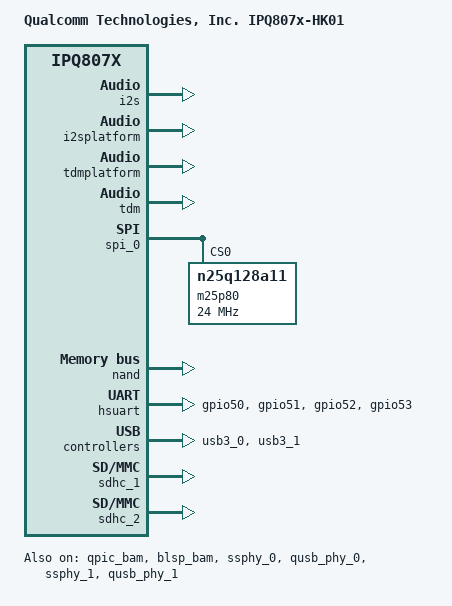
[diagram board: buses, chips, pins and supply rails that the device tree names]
/dts-v1/;
/*
 * Copyright (c) 2016, The Linux Foundation. All rights reserved.
 *
 * Permission to use, copy, modify, and/or distribute this software for any
 * purpose with or without fee is hereby granted, provided that the above
 * copyright notice and this permission notice appear in all copies.
 *
 * THE SOFTWARE IS PROVIDED "AS IS" AND THE AUTHOR DISCLAIMS ALL WARRANTIES
 * WITH REGARD TO THIS SOFTWARE INCLUDING ALL IMPLIED WARRANTIES OF
 * MERCHANTABILITY AND FITNESS. IN NO EVENT SHALL THE AUTHOR BE LIABLE FOR
 * ANY SPECIAL, DIRECT, INDIRECT, OR CONSEQUENTIAL DAMAGES OR ANY DAMAGES
 * WHATSOEVER RESULTING FROM LOSS OF USE, DATA OR PROFITS, WHETHER IN AN
 * ACTION OF CONTRACT, NEGLIGENCE OR OTHER TORTIOUS ACTION, ARISING OUT OF
 * OR IN CONNECTION WITH THE USE OR PERFORMANCE OF THIS SOFTWARE.
 */
#include "qcom-ipq807x-soc.dtsi"

/ {
	#address-cells = <0x2>;
	#size-cells = <0x2>;
	model = "Qualcomm Technologies, Inc. IPQ807x-HK01";
	compatible = "qcom,ipq807x-hk01", "qcom,ipq807x";
	qcom,msm-id = <0x125 0x0>;
	interrupt-parent = <&intc>;
	qcom,board-id = <0x10 0x0>;

	aliases {
		sdhc1 = &sdhc_1; /* SDC1 eMMC slot */
		sdhc2 = &sdhc_2; /* SDC2 SD slot */
	};

	cpus {
		#address-cells = <0x1>;
		#size-cells = <0x0>;

		cpu-map {

			cluster0 {

				core0 {
					cpu = <&CPU0>;
				};

				core1 {
					cpu = <&CPU1>;
				};

				core2 {
					cpu = <&CPU2>;
				};

				core3 {
					cpu = <&CPU3>;
				};
			};

		};

		CPU0: cpu@0 {
			device_type = "cpu";
			compatible = "arm,cortex-a53";
			reg = <0x0>;
			enable-method = "qcom,arm-cortex-acc";
			qcom,acc = <&acc0>;
			next-level-cache = <&L2_0>;

			L2_0: l2-cache {
				compatible = "arm,arch-cache";
				cache-level = <0x2>;
			};
		};

		CPU1: cpu@1 {
			device_type = "cpu";
			compatible = "arm,cortex-a53";
			enable-method = "qcom,arm-cortex-acc";
			reg = <0x1>;
			qcom,acc = <&acc1>;
			next-level-cache = <&L2_0>;
		};

		CPU2: cpu@2 {
			device_type = "cpu";
			compatible = "arm,cortex-a53";
			enable-method = "qcom,arm-cortex-acc";
			reg = <0x2>;
			qcom,acc = <&acc2>;
			next-level-cache = <&L2_0>;
		};

		CPU3: cpu@3 {
			device_type = "cpu";
			compatible = "arm,cortex-a53";
			enable-method = "qcom,arm-cortex-acc";
			reg = <0x3>;
			qcom,acc = <&acc3>;
			next-level-cache = <&L2_0>;
		};

	};

	chosen {
		bootargs = "console=ttyMSM0,115200,n8 root=/dev/ram0 rw \
			    init=/init";
	};

};

&soc {

	acc0:clock-controller@b188000 {
		compatible = "qcom,arm-cortex-acc";
		reg = <0x0b188000 0x1000>;
	};

	acc1:clock-controller@b198000 {
		compatible = "qcom,arm-cortex-acc";
		reg = <0x0b198000 0x1000>;
	};

	acc2:clock-controller@b1a8000 {
		compatible = "qcom,arm-cortex-acc";
		reg = <0x0b1a8000 0x1000>;
	};

	acc3:clock-controller@b1b8000 {
		compatible = "qcom,arm-cortex-acc";
		reg = <0x0b1b8000 0x1000>;
	};

	ess-switch@3a000000 {
		compatible = "qcom,ess-switch";
		reg = <0x3a000000 0x1000000>;
		switch_access_mode = "local bus";
	};

	audio: audio@7700000 {
		status = "ok";
	};

	mbox0: mbox@7708000 {
		status = "ok";
	};

	mbox3: mbox@770e000 {
		status = "ok";
	};

	stereo0: stereo@7709000 {
		status = "ok";
	};

	stereo3: stereo@770f000 {
		status = "ok";
	};

	/* Enable Audio Interfaces */
	i2s: ipq8074-pcm-i2s@0 {
		status = "ok";
	};

	i2splatform: qca-pcm-i2s@7709000 {
		status = "ok";
	};

	tdmplatform: qca-pcm-tdm@7709000 {
		status = "ok";
	};

	tdm: tdm@0 {
		status = "ok";
	};

	sound: sound@0 {
		pinctrl-0 = <&audio_gpio_pins>;
		pinctrl-1 = <&audio_pins>;
		pinctrl-names = "default", "audio";
		status = "ok";
	};

	/* Enable VOIP Interfaces */
	pcm: pcm@7704000 {
		status = "ok";
	};

	pcm_lb: pcm_lb@0 {
		status = "ok";
		pinctrl-0 = <&voip_pins>;
		pinctrl-names = "default";
	};
};

&tlmm {
	hsuart_pins: hsuart_pins {
		mux {
			pins = "gpio50", "gpio51", "gpio52", "gpio53";
			function = "blsp3_uart";
			bias-disable;
		};
	};

	audio_gpio_pins: audio_gpio_pinmux {
		mux_1 {
			pins = "gpio25";
			function = "gpio";
			bias-pull,up;
			output-high;
		};

		mux_2 {
			pins = "gpio26";
			function = "gpio";
			bias-pull,up;
			output-high;
		};

		mux_3 {
			pins = "gpio27";
			function = "gpio";
			bias-pull,up;
			output-high;
		};

		mux_4 {
			pins = "gpio28";
			function = "gpio";
			bias-pull,up;
			output-high;
		};

		mux_5 {
			pins = "gpio29";
			function = "gpio";
			bias-pull,up;
			output-high;
		};

		mux_6 {
			pins = "gpio30";
			function = "gpio";
			bias-pull,up;
			output-high;
		};

		mux_7 {
			pins = "gpio31";
			function = "gpio";
			bias-pull,up;
			output-high;
		};

		mux_8 {
			pins = "gpio32";
			function = "gpio";
			bias-pull,up;
			output-high;
		};
	};

	audio_pins: audio_pinmux {
		mux_1 {
			pins = "gpio25";
			function = "audio_txmclk";
			bias-pull,up;
		};

		mux_2 {
			pins = "gpio26";
			function = "audio_txbclk";
			bias-pull,up;
		};

		mux_3 {
			pins = "gpio27";
			function = "audio_txfsync";
			bias-pull,up;
		};

		mux_4 {
			pins = "gpio28";
			function = "audio_txd";
			bias-pull,up;
		};

		mux_5 {
			pins = "gpio29";
			function = "audio_rxmclk";
			bias-pull,up;
		};

		mux_6 {
			pins = "gpio30";
			function = "audio_rxbclk";
			bias-pull,up;
		};

		mux_7 {
			pins = "gpio31";
			function = "audio_rxfsync";
			bias-pull,up;
		};

		mux_8 {
			pins = "gpio32";
			function = "audio_rxd";
			bias-pull,up;
		};
	};

	voip_pins: voip_pinmux {
		mux_1 {
			pins = "gpio33";
			function = "pcm_drx";
			bias-pull,up;
		};

		mux_2 {
			pins = "gpio34";
			function = "pcm_dtx";
			bias-pull,up;
		};

		mux_3 {
			pins = "gpio35";
			function = "pcm_fsync";
			bias-pull,up;
		};

		mux_4 {
			pins = "gpio36";
			function = "pcm_pclk";
			bias-pull,up;
		};
	};
};

&spi_0 { /* BLSP1 QUP1 */
	#pinctrl-0 = <&spi_0_pins>;
	#pinctrl-names = "default";
	status = "ok";

	m25p80@0 {
		#address-cells = <1>;
		#size-cells = <1>;
		reg = <0>;
		compatible = "n25q128a11";
		linux,modalias = "m25p80", "n25q128a11";
		spi-max-frequency = <24000000>;
		use-default-sizes;
	};
};

&qpic_bam {
	status = "ok";
};

&nand {
	status = "ok";
};

&blsp_bam {
	status = "ok";
};

&hsuart {
	pinctrl-0 = <&hsuart_pins>;
	pinctrl-names = "default";
};

&ssphy_0 {
	qcom,emulation = <1>;
	status = "ok";
};

&qusb_phy_0 {
	qcom,emulation = <1>;
	status = "ok";
};

&ssphy_1 {
	qcom,emulation = <1>;
	status = "ok";
};

&qusb_phy_1 {
	qcom,emulation = <1>;
	status = "ok";
};

&dwc_0 {
	dr_mode = "peripheral";
};

&usb3_0 {
	status = "ok";
};

&usb3_1 {
	status = "ok";
};

&sdhc_1 {
	qcom,clk-rates = <400000 25000000 50000000 100000000 \
			 192000000 384000000>;
	qcom,bus-speed-mode = "DDR_1p8v";
	qcom,nonremovable;
	status = "ok";
};

&sdhc_2 {
	qcom,clk-rates = <400000 25000000 50000000 100000000 \
			 192000000 384000000>;
	qcom,bus-speed-mode = "HS200_1p8v", "DDR_1p8v";
	status = "ok";
};
